# hssi_ss_f_pfc_csr: IP-XACT component
VLNV Vendor:Library:hssi_ss_f_pfc_csr:1.0

## Bus interfaces (logical=physical port)
hssi_ss_f_pfc_csr_slave: slave Magillem:MRV:MRVBusDef:1.0, memory map hssi_ss_f_pfc_csr
  parameters _mre_definition_=hssi_ss_f_pfc_csr

## Ports
in pfccsrif_control_cfg_flow_control_en_gui_value[0:0]

## Address spaces and blocks
hssi_ss_f_pfc_csr.hssi_ss_f_pfc_csr_block: base 0x0, range 0xa0, width 32, register

## Registers
Registers are 32-bit, read-write, reset 0x0 unless marked. A register's access mark holds for its fields unless they carry their own. Offsets are from the block's base; lines under a group give offsets from that group; [hi:lo] are bit positions; {n}, {i} and the like mark numbered series; 'fields as' and 'values as' point back to an identical list; <NAME> marks a mode.

## hssi_ss_f_pfc_csr.hssi_ss_f_pfc_csr_block
Base 0x00000000
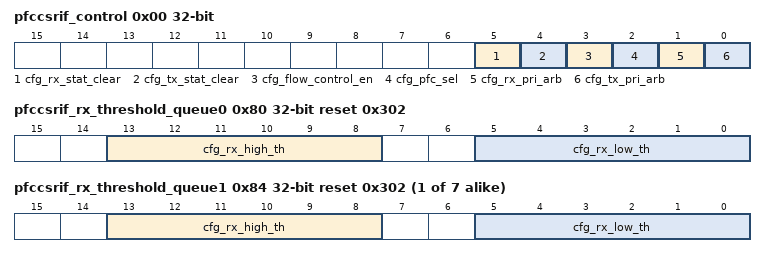
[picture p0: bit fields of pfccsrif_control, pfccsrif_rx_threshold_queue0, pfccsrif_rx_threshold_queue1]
0x00 pfccsrif_control (reset mask 0xFFFFFFF7) — <b>PFC Control</b>
  [5] cfg_rx_stat_clear — <b> Clear RX Statistics Counter</b>
  [4] cfg_tx_stat_clear — <b> Clear TX Statistics Counter</b>
  [3] cfg_flow_control_en — <b> Enable Flow control</b>
  [2] cfg_pfc_sel — <b>Select between Priority Flow control vs Standard Flow Control</b>
  [1] cfg_rx_pri_arb — <b>Indicate PFC Rx queue arbitration scheme</b>
  [0] cfg_tx_pri_arb — <b>Indicate PFC Tx queue arbitration scheme</b>
{0x20+4i} pfccsrif_tx_stat_queue{i} ro (i=0..7) — <b>PFC TX Queue {i} Statistics</b>
  [15:0] drop_pkt_cntr — <b>Indicate the packet drop count due to PFC TX queue {i} full</b>
{0x40+4i} pfccsrif_rx_stat_queue{i} ro (i=0..7) — <b>PFC RX Queue {i} Statistics</b>
  [15:0] drop_pkt_cntr — <b>Indicate the packet drop count due to PFC RX queue {i} full</b>
{0x60+4i} pfccsrif_tx_threshold_queue{i} reset 0x4 (i=0..7) — <b>PFC TX Queue {i} Threshold</b>
  [2:0] cfg_tx_th — <b>TX threshold expressed as a percentage of TX-Queue size</b>
0x80 pfccsrif_rx_threshold_queue0 reset 0x302 — <b>PFC RX Queue 0 Threshold</b>
  [13:8] cfg_rx_high_th — <b>cfg_rx_high_th[Q] => Sets the high threshold for RX-Queue. Value is calculated as cfg_rx_high_th[Q] * 128. Tx_pfc/pause is asserted if fill level is >= this value</b>
  [5:0] cfg_rx_low_th — <b>cfg_rx_low_th[Q] => Sets the low threshold for RX-Queue. Value is calculated as cfg_rx_low_th[Q] * 128. Tx_pfc/pause is de-asserted if fill level is < this value</b>
{0x80+4i} pfccsrif_rx_threshold_queue{i} reset 0x302 (i=1..7) — <b>PFC RX Queue 1 Threshold</b>
  fields as pfccsrif_rx_threshold_queue0
